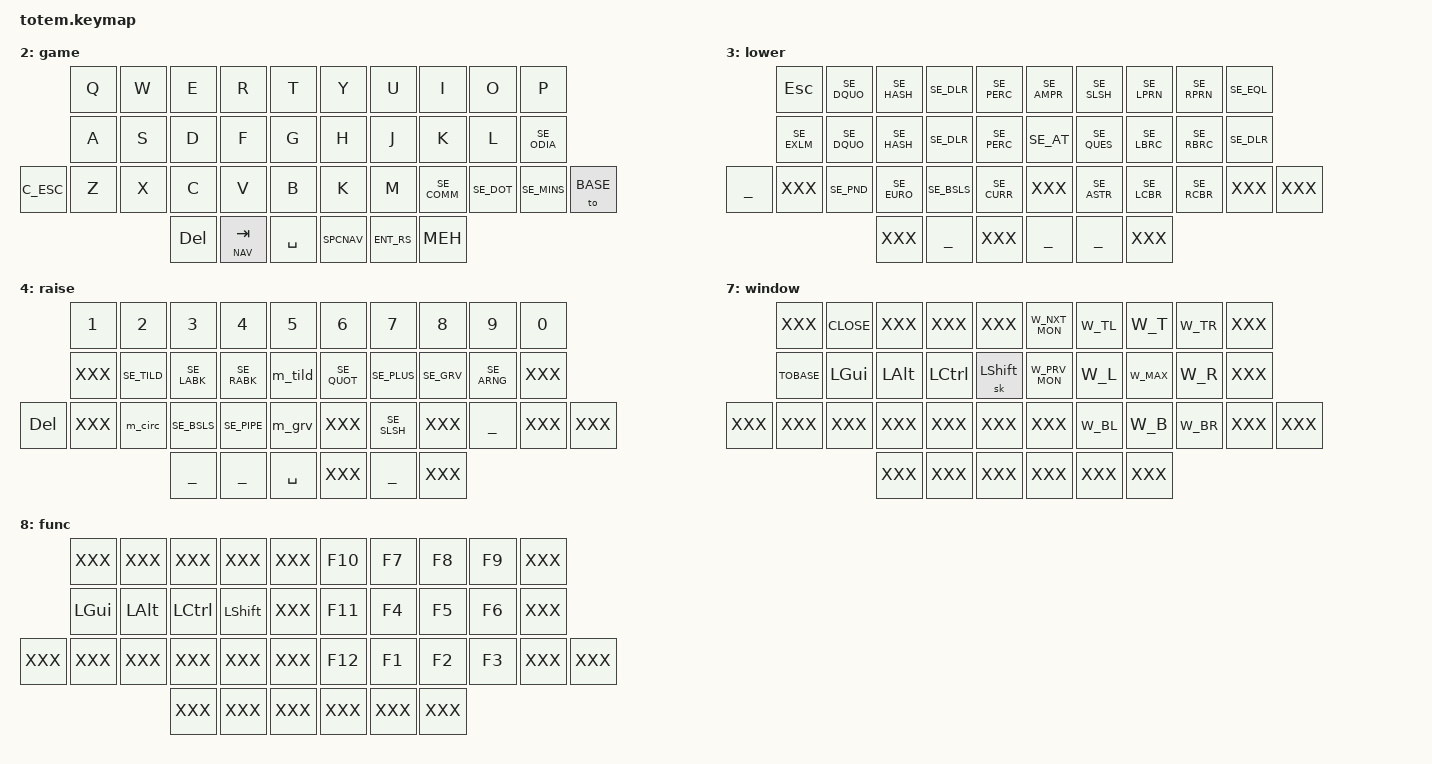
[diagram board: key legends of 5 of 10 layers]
//
//                                                        ▀▀▀▀▀     ▀▀▀▀▀          ▀▀█▀▀
//                                                        ▄▀▀▀▄  ▄  ▄▀▀▀▄  ▄  ▄▀▀▀▄  █  ▄▀▀▀▄
//                                                        █   █  █  █   █  █  █   █  █  █   █
//                                                         ▀▀▀   █   ▀▀▀   █   ▀▀▀   ▀   ▀▀▀
//                                                               █      ▄▄▄█▄▄▄    █   █
//                                                               ▀      █  █  █     █▄█
//                                                             ▀▀▀▀▀    █  █  █      ▀
//                                                                      ▀  ▀  ▀
//
// ▄▄▄▄▄▄▄▄▄▄▄▄▄▄▄▄▄▄▄▄▄▄▄▄▄▄▄▄▄▄▄▄▄▄▄▄▄▄▄▄▄▄▄▄▄▄▄▄▄▄▄▄▄▄▄▄▄▄▄▄▄▄▄▄▄▄▄▄▄▄▄▄▄▄▄▄▄▄▄▄▄▄▄▄▄▄▄▄▄▄▄▄▄▄▄▄▄▄▄▄▄▄▄▄▄▄▄▄▄▄▄▄▄▄▄▄▄▄▄▄▄▄▄▄▄▄▄▄▄▄▄▄▄▄▄▄▄▄▄▄▄▄▄▄▄▄▄▄▄


#include <behaviors.dtsi>
#include <dt-bindings/zmk/keys.h>
#include <dt-bindings/zmk/bt.h>
#include <dt-bindings/zmk/outputs.h>

#include "zmk-helpers/helper.h"
#include "zmk-helpers/key-labels/totem.h"
#include "../shared/swedish.h"
#include "totem.h"
#include "homerow_mods.h"
#include "combos.dtsi"
#include "../shared/macros.dtsi"

// tap: sticky-shift | shift + tap/ double-tap: caps-word | hold: shift
ZMK_BEHAVIOR(smart_shft, mod_morph,
    bindings = <&sk LSHFT>, <&caps_word>;
    mods = <(MOD_LSFT)>;
)

&caps_word {
    continue-list = <SE_UNDS SE_MINS BACKSPACE>;
    /delete-property/ ignore-modifiers;
};

&sk {  // sticky-key config
    release-after-ms = <900>;  // release after 0.9s
    quick-release;             // no double capitalization when rolling keys
};

&sl {  // sticky-layer config
    ignore-modifiers;          // allow chording sticky mods & layers
};

&mt {
  flavor = "tap-preferred";
  tapping-term-ms = <220>;
  quick-tap-ms = <220>;
  hold-trigger-key-positions = <0>;
};

&lt {  // layer-tap config
    flavor = "balanced";
    tapping-term-ms = <200>;
    quick-tap-ms = <QUICK_TAP_MS>;
};

&soft_off {
    hold-time-ms = <3000>; // Hold for 3s to turn off
};

ZMK_CONDITIONAL_LAYER(adj_layer, LOWER RAISE, ADJUST)

// clang-format off
ZMK_LAYER(base,
//             ┏━━━━━━━━━━━┳━━━━━━━━━━━┳━━━━━━━━━━━┳━━━━━━━━━━━┳━━━━━━━━━━━┓   ┏━━━━━━━━━━━┳━━━━━━━━━━━┳━━━━━━━━━━━┳━━━━━━━━━━━┳━━━━━━━━━━━┓
                &kp Q       &kp W       &kp E       &kp R       &kp T           &kp Y       &kp U       &kp I       &kp O       &kp P
//             ┣━━━━━━━━━━━╋━━━━━━━━━━━╋━━━━━━━━━━━╋━━━━━━━━━━━╋━━━━━━━━━━━┫   ┣━━━━━━━━━━━╋━━━━━━━━━━━╋━━━━━━━━━━━╋━━━━━━━━━━━╋━━━━━━━━━━━┫
                HRM_A       HRM_S       HRM_D       HRM_F       &kp G           &kp H       HRM_J       HRM_K       HRM_L       HRM_OE
// ┏━━━━━━━━━━━╋━━━━━━━━━━━╋━━━━━━━━━━━╋━━━━━━━━━━━╋━━━━━━━━━━━╋━━━━━━━━━━━┫   ┣━━━━━━━━━━━╋━━━━━━━━━━━╋━━━━━━━━━━━╋━━━━━━━━━━━╋━━━━━━━━━━━╋━━━━━━━━━━━┓
    C_ESC       &kp Z       &kp X       &kp C       &kp V       &kp B           &kp N       &kp M       &kp SE_COMM &kp SE_DOT  &kp SE_MINS &kp SE_ADIA
// ┗━━━━━━━━━━━┻━━━━━━━━━━━┻━━━━━━━━━━━╋━━━━━━━━━━━╋━━━━━━━━━━━╋━━━━━━━━━━━┫   ┣━━━━━━━━━━━╋━━━━━━━━━━━╋━━━━━━━━━━━╋━━━━━━━━━━━┻━━━━━━━━━━━┻━━━━━━━━━━━┛
                                        &smart_shft BS_LOW      TABNUM          SPCNAV      ENT_RS      &sk MEH
//                                     ┗━━━━━━━━━━━┻━━━━━━━━━━━┻━━━━━━━━━━━┛   ┗━━━━━━━━━━━┻━━━━━━━━━━━┻━━━━━━━━━━━┛
)
// ▄▄▄▄▄▄▄▄▄▄▄▄▄▄▄▄▄▄▄▄▄▄▄▄▄▄▄▄▄▄▄▄▄▄▄▄▄▄▄▄▄▄▄▄▄▄▄▄▄▄▄▄▄▄▄▄▄▄▄▄▄▄▄▄▄▄▄▄▄▄▄▄▄▄▄▄▄▄▄▄▄▄▄▄▄▄▄▄▄▄▄▄▄▄▄▄▄▄▄▄▄▄▄▄▄▄▄▄▄▄▄▄▄▄▄▄▄▄▄▄▄▄▄▄▄▄▄▄▄▄▄▄▄▄▄▄▄▄▄▄▄▄▄▄▄▄▄▄▄

ZMK_LAYER(col,
//             ┏━━━━━━━━━━━┳━━━━━━━━━━━┳━━━━━━━━━━━┳━━━━━━━━━━━┳━━━━━━━━━━━┓   ┏━━━━━━━━━━━┳━━━━━━━━━━━┳━━━━━━━━━━━┳━━━━━━━━━━━┳━━━━━━━━━━━┓
                &kp Q       &kp W       &kp F       &kp P       &kp B           &kp J       &kp L       &kp U       &kp Y       &kp SE_ODIA
//             ┣━━━━━━━━━━━╋━━━━━━━━━━━╋━━━━━━━━━━━╋━━━━━━━━━━━╋━━━━━━━━━━━┫   ┣━━━━━━━━━━━╋━━━━━━━━━━━╋━━━━━━━━━━━╋━━━━━━━━━━━╋━━━━━━━━━━━┫
                &kp A       &kp R       &kp S       &kp T       &kp G           &kp M       &kp N       &kp E       &kp I       &kp O
// ┏━━━━━━━━━━━╋━━━━━━━━━━━╋━━━━━━━━━━━╋━━━━━━━━━━━╋━━━━━━━━━━━╋━━━━━━━━━━━┫   ┣━━━━━━━━━━━╋━━━━━━━━━━━╋━━━━━━━━━━━╋━━━━━━━━━━━╋━━━━━━━━━━━╋━━━━━━━━━━━┓
    C_ESC       &kp Z       &kp X       &kp C       &kp D       &kp V           &kp K       &kp H       &kp SE_COMM &kp SE_DOT  &kp SE_MINS &kp SE_ADIA
// ┗━━━━━━━━━━━┻━━━━━━━━━━━┻━━━━━━━━━━━╋━━━━━━━━━━━╋━━━━━━━━━━━╋━━━━━━━━━━━┫   ┣━━━━━━━━━━━╋━━━━━━━━━━━╋━━━━━━━━━━━╋━━━━━━━━━━━┻━━━━━━━━━━━┻━━━━━━━━━━━┛
                                        &smart_shft BS_LOW      TABNUM          SPCNAV      ENT_RS      &sk MEH
//                                     ┗━━━━━━━━━━━┻━━━━━━━━━━━┻━━━━━━━━━━━┛   ┗━━━━━━━━━━━┻━━━━━━━━━━━┻━━━━━━━━━━━┛
)
// ▄▄▄▄▄▄▄▄▄▄▄▄▄▄▄▄▄▄▄▄▄▄▄▄▄▄▄▄▄▄▄▄▄▄▄▄▄▄▄▄▄▄▄▄▄▄▄▄▄▄▄▄▄▄▄▄▄▄▄▄▄▄▄▄▄▄▄▄▄▄▄▄▄▄▄▄▄▄▄▄▄▄▄▄▄▄▄▄▄▄▄▄▄▄▄▄▄▄▄▄▄▄▄▄▄▄▄▄▄▄▄▄▄▄▄▄▄▄▄▄▄▄▄▄▄▄▄▄▄▄▄▄▄▄▄▄▄▄▄▄▄▄▄▄▄▄▄▄▄

ZMK_LAYER(game,
//             ┏━━━━━━━━━━━┳━━━━━━━━━━━┳━━━━━━━━━━━┳━━━━━━━━━━━┳━━━━━━━━━━━┓   ┏━━━━━━━━━━━┳━━━━━━━━━━━┳━━━━━━━━━━━┳━━━━━━━━━━━┳━━━━━━━━━━━┓
                &kp Q       &kp W       &kp E       &kp R       &kp T           &kp Y       &kp U       &kp I       &kp O       &kp P
//             ┣━━━━━━━━━━━╋━━━━━━━━━━━╋━━━━━━━━━━━╋━━━━━━━━━━━╋━━━━━━━━━━━┫   ┣━━━━━━━━━━━╋━━━━━━━━━━━╋━━━━━━━━━━━╋━━━━━━━━━━━╋━━━━━━━━━━━┫
                &kp A       &kp S       &kp D       &kp F       &kp G           &kp H       &kp J       &kp K       &kp L       &kp SE_ODIA
// ┏━━━━━━━━━━━╋━━━━━━━━━━━╋━━━━━━━━━━━╋━━━━━━━━━━━╋━━━━━━━━━━━╋━━━━━━━━━━━┫   ┣━━━━━━━━━━━╋━━━━━━━━━━━╋━━━━━━━━━━━╋━━━━━━━━━━━╋━━━━━━━━━━━╋━━━━━━━━━━━┓
    C_ESC       &kp Z       &kp X       &kp C       &kp V       &kp B           &kp K       &kp M       &kp SE_COMM &kp SE_DOT  &kp SE_MINS &to BASE
// ┗━━━━━━━━━━━┻━━━━━━━━━━━┻━━━━━━━━━━━╋━━━━━━━━━━━╋━━━━━━━━━━━╋━━━━━━━━━━━┫   ┣━━━━━━━━━━━╋━━━━━━━━━━━╋━━━━━━━━━━━╋━━━━━━━━━━━┻━━━━━━━━━━━┻━━━━━━━━━━━┛
                                        &kp DEL     &lt NAV TAB &kp SPACE       SPCNAV      ENT_RS      &kp MEH
//                                     ┗━━━━━━━━━━━┻━━━━━━━━━━━┻━━━━━━━━━━━┛   ┗━━━━━━━━━━━┻━━━━━━━━━━━┻━━━━━━━━━━━┛
)
// ▄▄▄▄▄▄▄▄▄▄▄▄▄▄▄▄▄▄▄▄▄▄▄▄▄▄▄▄▄▄▄▄▄▄▄▄▄▄▄▄▄▄▄▄▄▄▄▄▄▄▄▄▄▄▄▄▄▄▄▄▄▄▄▄▄▄▄▄▄▄▄▄▄▄▄▄▄▄▄▄▄▄▄▄▄▄▄▄▄▄▄▄▄▄▄▄▄▄▄▄▄▄▄▄▄▄▄▄▄▄▄▄▄▄▄▄▄▄▄▄▄▄▄▄▄▄▄▄▄▄▄▄▄▄▄▄▄▄▄▄▄▄▄▄▄▄▄▄▄

ZMK_LAYER(lower,
//             ┏━━━━━━━━━━━┳━━━━━━━━━━━┳━━━━━━━━━━━┳━━━━━━━━━━━┳━━━━━━━━━━━┓   ┏━━━━━━━━━━━┳━━━━━━━━━━━┳━━━━━━━━━━━┳━━━━━━━━━━━┳━━━━━━━━━━━┓
                &kp ESC     &kp SE_DQUO &kp SE_HASH &kp SE_DLR  &kp SE_PERC     &kp SE_AMPR &kp SE_SLSH &kp SE_LPRN &kp SE_RPRN &kp SE_EQL
//             ┣━━━━━━━━━━━╋━━━━━━━━━━━╋━━━━━━━━━━━╋━━━━━━━━━━━╋━━━━━━━━━━━┫   ┣━━━━━━━━━━━╋━━━━━━━━━━━╋━━━━━━━━━━━╋━━━━━━━━━━━╋━━━━━━━━━━━┫
                &kp SE_EXLM &kp SE_DQUO &kp SE_HASH &kp SE_DLR  &kp SE_PERC     &kp SE_AT   &kp SE_QUES &kp SE_LBRC &kp SE_RBRC &kp SE_DLR
// ┏━━━━━━━━━━━╋━━━━━━━━━━━╋━━━━━━━━━━━╋━━━━━━━━━━━╋━━━━━━━━━━━╋━━━━━━━━━━━┫   ┣━━━━━━━━━━━╋━━━━━━━━━━━╋━━━━━━━━━━━╋━━━━━━━━━━━╋━━━━━━━━━━━╋━━━━━━━━━━━┓
    ___         XXX         &kp SE_PND  &kp SE_EURO &kp SE_BSLS &kp SE_CURR     XXX         &kp SE_ASTR &kp SE_LCBR &kp SE_RCBR XXX         XXX
// ┗━━━━━━━━━━━┻━━━━━━━━━━━┻━━━━━━━━━━━╋━━━━━━━━━━━╋━━━━━━━━━━━╋━━━━━━━━━━━┫   ┣━━━━━━━━━━━╋━━━━━━━━━━━╋━━━━━━━━━━━╋━━━━━━━━━━━┻━━━━━━━━━━━┻━━━━━━━━━━━┛
                                        XXX         ___         XXX             ___         ___         XXX
//                                     ┗━━━━━━━━━━━┻━━━━━━━━━━━┻━━━━━━━━━━━┛   ┗━━━━━━━━━━━┻━━━━━━━━━━━┻━━━━━━━━━━━┛
)
// ▄▄▄▄▄▄▄▄▄▄▄▄▄▄▄▄▄▄▄▄▄▄▄▄▄▄▄▄▄▄▄▄▄▄▄▄▄▄▄▄▄▄▄▄▄▄▄▄▄▄▄▄▄▄▄▄▄▄▄▄▄▄▄▄▄▄▄▄▄▄▄▄▄▄▄▄▄▄▄▄▄▄▄▄▄▄▄▄▄▄▄▄▄▄▄▄▄▄▄▄▄▄▄▄▄▄▄▄▄▄▄▄▄▄▄▄▄▄▄▄▄▄▄▄▄▄▄▄▄▄▄▄▄▄▄▄▄▄▄▄▄▄▄▄▄▄▄▄▄

ZMK_LAYER(raise,
//             ┏━━━━━━━━━━━┳━━━━━━━━━━━┳━━━━━━━━━━━┳━━━━━━━━━━━┳━━━━━━━━━━━┓   ┏━━━━━━━━━━━┳━━━━━━━━━━━┳━━━━━━━━━━━┳━━━━━━━━━━━┳━━━━━━━━━━━┓
                &kp N1      &kp N2      &kp N3      &kp N4      &kp N5          &kp N6      &kp N7      &kp N8      &kp N9      &kp N0
//             ┣━━━━━━━━━━━╋━━━━━━━━━━━╋━━━━━━━━━━━╋━━━━━━━━━━━╋━━━━━━━━━━━┫   ┣━━━━━━━━━━━╋━━━━━━━━━━━╋━━━━━━━━━━━╋━━━━━━━━━━━╋━━━━━━━━━━━┫
                XXX         &kp SE_TILD &kp SE_LABK &kp SE_RABK &m_tild         &kp SE_QUOT &kp SE_PLUS &kp SE_GRV  &kp SE_ARNG XXX
// ┏━━━━━━━━━━━╋━━━━━━━━━━━╋━━━━━━━━━━━╋━━━━━━━━━━━╋━━━━━━━━━━━╋━━━━━━━━━━━┫   ┣━━━━━━━━━━━╋━━━━━━━━━━━╋━━━━━━━━━━━╋━━━━━━━━━━━╋━━━━━━━━━━━╋━━━━━━━━━━━┓
    &kp DEL     XXX         &m_circ     &kp SE_BSLS &kp SE_PIPE &m_grv          XXX         &kp SE_SLSH XXX         ___         XXX           XXX
// ┗━━━━━━━━━━━┻━━━━━━━━━━━┻━━━━━━━━━━━╋━━━━━━━━━━━╋━━━━━━━━━━━╋━━━━━━━━━━━┫   ┣━━━━━━━━━━━╋━━━━━━━━━━━╋━━━━━━━━━━━╋━━━━━━━━━━━┻━━━━━━━━━━━┻━━━━━━━━━━━┛
                                        ___         ___         &kp SPACE       XXX         ___         XXX
//                                     ┗━━━━━━━━━━━┻━━━━━━━━━━━┻━━━━━━━━━━━┛   ┗━━━━━━━━━━━┻━━━━━━━━━━━┻━━━━━━━━━━━┛
)
// ▄▄▄▄▄▄▄▄▄▄▄▄▄▄▄▄▄▄▄▄▄▄▄▄▄▄▄▄▄▄▄▄▄▄▄▄▄▄▄▄▄▄▄▄▄▄▄▄▄▄▄▄▄▄▄▄▄▄▄▄▄▄▄▄▄▄▄▄▄▄▄▄▄▄▄▄▄▄▄▄▄▄▄▄▄▄▄▄▄▄▄▄▄▄▄▄▄▄▄▄▄▄▄▄▄▄▄▄▄▄▄▄▄▄▄▄▄▄▄▄▄▄▄▄▄▄▄▄▄▄▄▄▄▄▄▄▄▄▄▄▄▄▄▄▄▄▄▄▄

ZMK_LAYER(nav,
//             ┏━━━━━━━━━━━┳━━━━━━━━━━━┳━━━━━━━━━━━┳━━━━━━━━━━━┳━━━━━━━━━━━┓   ┏━━━━━━━━━━━┳━━━━━━━━━━━┳━━━━━━━━━━━┳━━━━━━━━━━━┳━━━━━━━━━━━┓
                &sl WINDOW  &kp LGUI    &kp LALT    XXX         &kp PG_UP       YANK        TAB_PREV    &m_forward  TAB_NEXT    PASTE
//             ┣━━━━━━━━━━━╋━━━━━━━━━━━╋━━━━━━━━━━━╋━━━━━━━━━━━╋━━━━━━━━━━━┫   ┣━━━━━━━━━━━╋━━━━━━━━━━━╋━━━━━━━━━━━╋━━━━━━━━━━━╋━━━━━━━━━━━┫
                &kp HOME    &kp END     &kp LCTRL   &kp LSHFT   &kp PG_DN       &kp LEFT    &kp DOWN    &kp UP      &kp RIGHT   &kp DEL
// ┏━━━━━━━━━━━╋━━━━━━━━━━━╋━━━━━━━━━━━╋━━━━━━━━━━━╋━━━━━━━━━━━╋━━━━━━━━━━━┫   ┣━━━━━━━━━━━╋━━━━━━━━━━━╋━━━━━━━━━━━╋━━━━━━━━━━━╋━━━━━━━━━━━╋━━━━━━━━━━━┓
    XXX         XXX         DLINE       COMNT       DUPLIC      XXX             CLeft       YANK        PASTE       CRight      XXX         &kp PSCRN
// ┗━━━━━━━━━━━┻━━━━━━━━━━━┻━━━━━━━━━━━╋━━━━━━━━━━━╋━━━━━━━━━━━╋━━━━━━━━━━━┫   ┣━━━━━━━━━━━╋━━━━━━━━━━━╋━━━━━━━━━━━╋━━━━━━━━━━━┻━━━━━━━━━━━┻━━━━━━━━━━━┛
                                        XXX         &kp BSPC    &kp TAB         TOBASE      &kp ENTER   XXX
//                                     ┗━━━━━━━━━━━┻━━━━━━━━━━━┻━━━━━━━━━━━┛   ┗━━━━━━━━━━━┻━━━━━━━━━━━┻━━━━━━━━━━━┛
)
// ▄▄▄▄▄▄▄▄▄▄▄▄▄▄▄▄▄▄▄▄▄▄▄▄▄▄▄▄▄▄▄▄▄▄▄▄▄▄▄▄▄▄▄▄▄▄▄▄▄▄▄▄▄▄▄▄▄▄▄▄▄▄▄▄▄▄▄▄▄▄▄▄▄▄▄▄▄▄▄▄▄▄▄▄▄▄▄▄▄▄▄▄▄▄▄▄▄▄▄▄▄▄▄▄▄▄▄▄▄▄▄▄▄▄▄▄▄▄▄▄▄▄▄▄▄▄▄▄▄▄▄▄▄▄▄▄▄▄▄▄▄▄▄▄▄▄▄▄▄

ZMK_LAYER(num,
//             ┏━━━━━━━━━━━┳━━━━━━━━━━━┳━━━━━━━━━━━┳━━━━━━━━━━━┳━━━━━━━━━━━┓   ┏━━━━━━━━━━━┳━━━━━━━━━━━┳━━━━━━━━━━━┳━━━━━━━━━━━┳━━━━━━━━━━━┓
                XXX         TAB_PREV    &m_back     TAB_NEXT    &sl FUNC        &kp KP_DIVIDE &kp N7    &kp N8      &kp N9      &kp KP_MULTIPLY
//             ┣━━━━━━━━━━━╋━━━━━━━━━━━╋━━━━━━━━━━━╋━━━━━━━━━━━╋━━━━━━━━━━━┫   ┣━━━━━━━━━━━╋━━━━━━━━━━━╋━━━━━━━━━━━╋━━━━━━━━━━━╋━━━━━━━━━━━┫
                XXX         KUT         YANK        PASTE       NEXT            &kp BSPC    &kp N4      &kp N5      &kp N6      &kp KP_MINUS
// ┏━━━━━━━━━━━╋━━━━━━━━━━━╋━━━━━━━━━━━╋━━━━━━━━━━━╋━━━━━━━━━━━╋━━━━━━━━━━━┫   ┣━━━━━━━━━━━╋━━━━━━━━━━━╋━━━━━━━━━━━╋━━━━━━━━━━━╋━━━━━━━━━━━╋━━━━━━━━━━━┓
    XXX         XXX         XXX         XXX         XXX         XXX             &kp TAB     &kp N1      &kp N2      &kp N3      &kp KP_PLUS &caps_word
// ┗━━━━━━━━━━━┻━━━━━━━━━━━┻━━━━━━━━━━━╋━━━━━━━━━━━╋━━━━━━━━━━━╋━━━━━━━━━━━┫   ┣━━━━━━━━━━━╋━━━━━━━━━━━╋━━━━━━━━━━━╋━━━━━━━━━━━┻━━━━━━━━━━━┻━━━━━━━━━━━┛
                                        XXX         XXX         XXX             &kp SPACE   &kp N0      &kp ENTER
//                                     ┗━━━━━━━━━━━┻━━━━━━━━━━━┻━━━━━━━━━━━┛   ┗━━━━━━━━━━━┻━━━━━━━━━━━┻━━━━━━━━━━━┛
)
// ▄▄▄▄▄▄▄▄▄▄▄▄▄▄▄▄▄▄▄▄▄▄▄▄▄▄▄▄▄▄▄▄▄▄▄▄▄▄▄▄▄▄▄▄▄▄▄▄▄▄▄▄▄▄▄▄▄▄▄▄▄▄▄▄▄▄▄▄▄▄▄▄▄▄▄▄▄▄▄▄▄▄▄▄▄▄▄▄▄▄▄▄▄▄▄▄▄▄▄▄▄▄▄▄▄▄▄▄▄▄▄▄▄▄▄▄▄▄▄▄▄▄▄▄▄▄▄▄▄▄▄▄▄▄▄▄▄▄▄▄▄▄▄▄▄▄▄▄▄

ZMK_LAYER(window,
//             ┏━━━━━━━━━━━┳━━━━━━━━━━━┳━━━━━━━━━━━┳━━━━━━━━━━━┳━━━━━━━━━━━┓   ┏━━━━━━━━━━━┳━━━━━━━━━━━┳━━━━━━━━━━━┳━━━━━━━━━━━┳━━━━━━━━━━━┓
                XXX         CLOSE       XXX         XXX         XXX             W_NXT_MON   W_TL        W_T         W_TR        XXX
//             ┣━━━━━━━━━━━╋━━━━━━━━━━━╋━━━━━━━━━━━╋━━━━━━━━━━━╋━━━━━━━━━━━┫   ┣━━━━━━━━━━━╋━━━━━━━━━━━╋━━━━━━━━━━━╋━━━━━━━━━━━╋━━━━━━━━━━━┫
                TOBASE      &kp LGUI    &kp LALT    &kp LCTRL   &sk LSHFT       W_PRV_MON   W_L         W_MAX       W_R         XXX
// ┏━━━━━━━━━━━╋━━━━━━━━━━━╋━━━━━━━━━━━╋━━━━━━━━━━━╋━━━━━━━━━━━╋━━━━━━━━━━━┫   ┣━━━━━━━━━━━╋━━━━━━━━━━━╋━━━━━━━━━━━╋━━━━━━━━━━━╋━━━━━━━━━━━╋━━━━━━━━━━━┓
    XXX         XXX         XXX         XXX         XXX         XXX             XXX         W_BL        W_B         W_BR        XXX         XXX
// ┗━━━━━━━━━━━┻━━━━━━━━━━━┻━━━━━━━━━━━╋━━━━━━━━━━━╋━━━━━━━━━━━╋━━━━━━━━━━━┫   ┣━━━━━━━━━━━╋━━━━━━━━━━━╋━━━━━━━━━━━╋━━━━━━━━━━━┻━━━━━━━━━━━┻━━━━━━━━━━━┛
                                        XXX         XXX         XXX             XXX         XXX         XXX
//                                     ┗━━━━━━━━━━━┻━━━━━━━━━━━┻━━━━━━━━━━━┛   ┗━━━━━━━━━━━┻━━━━━━━━━━━┻━━━━━━━━━━━┛
)
// ▄▄▄▄▄▄▄▄▄▄▄▄▄▄▄▄▄▄▄▄▄▄▄▄▄▄▄▄▄▄▄▄▄▄▄▄▄▄▄▄▄▄▄▄▄▄▄▄▄▄▄▄▄▄▄▄▄▄▄▄▄▄▄▄▄▄▄▄▄▄▄▄▄▄▄▄▄▄▄▄▄▄▄▄▄▄▄▄▄▄▄▄▄▄▄▄▄▄▄▄▄▄▄▄▄▄▄▄▄▄▄▄▄▄▄▄▄▄▄▄▄▄▄▄▄▄▄▄▄▄▄▄▄▄▄▄▄▄▄▄▄▄▄▄▄▄▄▄▄

ZMK_LAYER(func,
//             ┏━━━━━━━━━━━┳━━━━━━━━━━━┳━━━━━━━━━━━┳━━━━━━━━━━━┳━━━━━━━━━━━┓   ┏━━━━━━━━━━━┳━━━━━━━━━━━┳━━━━━━━━━━━┳━━━━━━━━━━━┳━━━━━━━━━━━┓
                XXX         XXX         XXX         XXX         XXX             &kp F10     &kp F7      &kp F8      &kp F9      XXX
//             ┣━━━━━━━━━━━╋━━━━━━━━━━━╋━━━━━━━━━━━╋━━━━━━━━━━━╋━━━━━━━━━━━┫   ┣━━━━━━━━━━━╋━━━━━━━━━━━╋━━━━━━━━━━━╋━━━━━━━━━━━╋━━━━━━━━━━━┫
                &kp LGUI    &kp LALT    &kp LCTRL   &kp LSHFT   XXX             &kp F11     &kp F4      &kp F5      &kp F6      XXX
// ┏━━━━━━━━━━━╋━━━━━━━━━━━╋━━━━━━━━━━━╋━━━━━━━━━━━╋━━━━━━━━━━━╋━━━━━━━━━━━┫   ┣━━━━━━━━━━━╋━━━━━━━━━━━╋━━━━━━━━━━━╋━━━━━━━━━━━╋━━━━━━━━━━━╋━━━━━━━━━━━┓
    XXX         XXX         XXX         XXX         XXX         XXX             &kp F12     &kp F1      &kp F2      &kp F3      XXX         XXX
// ┗━━━━━━━━━━━┻━━━━━━━━━━━┻━━━━━━━━━━━╋━━━━━━━━━━━╋━━━━━━━━━━━╋━━━━━━━━━━━┫   ┣━━━━━━━━━━━╋━━━━━━━━━━━╋━━━━━━━━━━━╋━━━━━━━━━━━┻━━━━━━━━━━━┻━━━━━━━━━━━┛
                                        XXX         XXX         XXX             XXX         XXX         XXX
//                                     ┗━━━━━━━━━━━┻━━━━━━━━━━━┻━━━━━━━━━━━┛   ┗━━━━━━━━━━━┻━━━━━━━━━━━┻━━━━━━━━━━━┛
)
// ▄▄▄▄▄▄▄▄▄▄▄▄▄▄▄▄▄▄▄▄▄▄▄▄▄▄▄▄▄▄▄▄▄▄▄▄▄▄▄▄▄▄▄▄▄▄▄▄▄▄▄▄▄▄▄▄▄▄▄▄▄▄▄▄▄▄▄▄▄▄▄▄▄▄▄▄▄▄▄▄▄▄▄▄▄▄▄▄▄▄▄▄▄▄▄▄▄▄▄▄▄▄▄▄▄▄▄▄▄▄▄▄▄▄▄▄▄▄▄▄▄▄▄▄▄▄▄▄▄▄▄▄▄▄▄▄▄▄▄▄▄▄▄▄▄▄▄▄▄

ZMK_LAYER(adj,
//             ┏━━━━━━━━━━━┳━━━━━━━━━━━┳━━━━━━━━━━━┳━━━━━━━━━━━┳━━━━━━━━━━━┓   ┏━━━━━━━━━━━┳━━━━━━━━━━━┳━━━━━━━━━━━┳━━━━━━━━━━━┳━━━━━━━━━━━┓
                &sys_reset  &bootloader &to BASE    &to CLMDH   &to GAME        &studio_unlock &kp F7      &kp F8      &kp F9      &kp F12
//             ┣━━━━━━━━━━━╋━━━━━━━━━━━╋━━━━━━━━━━━╋━━━━━━━━━━━╋━━━━━━━━━━━┫   ┣━━━━━━━━━━━╋━━━━━━━━━━━╋━━━━━━━━━━━╋━━━━━━━━━━━╋━━━━━━━━━━━┫
                BT_CH_3     BT_CH_2     BT_CH_1     BT_CH_0     &soft_off       XXX         &kp F4      &kp F5      &kp F6      &kp F11
// ┏━━━━━━━━━━━╋━━━━━━━━━━━╋━━━━━━━━━━━╋━━━━━━━━━━━╋━━━━━━━━━━━╋━━━━━━━━━━━┫   ┣━━━━━━━━━━━╋━━━━━━━━━━━╋━━━━━━━━━━━╋━━━━━━━━━━━╋━━━━━━━━━━━╋━━━━━━━━━━━┓
    &bt BT_CLR  GO_USB      GO_BLE      XXX         BT_CH_4     XXX             XXX         &kp F1      &kp F2      &kp F3      &kp F10     XXX
// ┗━━━━━━━━━━━┻━━━━━━━━━━━┻━━━━━━━━━━━╋━━━━━━━━━━━╋━━━━━━━━━━━╋━━━━━━━━━━━┫   ┣━━━━━━━━━━━╋━━━━━━━━━━━╋━━━━━━━━━━━╋━━━━━━━━━━━┻━━━━━━━━━━━┻━━━━━━━━━━━┛
                                        XXX         XXX         XXX             XXX         XXX         XXX
//                                     ┗━━━━━━━━━━━┻━━━━━━━━━━━┻━━━━━━━━━━━┛   ┗━━━━━━━━━━━┻━━━━━━━━━━━┻━━━━━━━━━━━┛
)
// clang-format on
